# STM32W108 register map
File version: 1.0
Registers are 32-bit, read-write, reset 0x0 unless marked. A register's access mark holds for its fields unless they carry their own. Offsets are from the block's base; [hi:lo] are bit positions; {n}, {i} and the like mark numbered series.

## TIM2 — General purpose timer 2
Base 0x4000A804
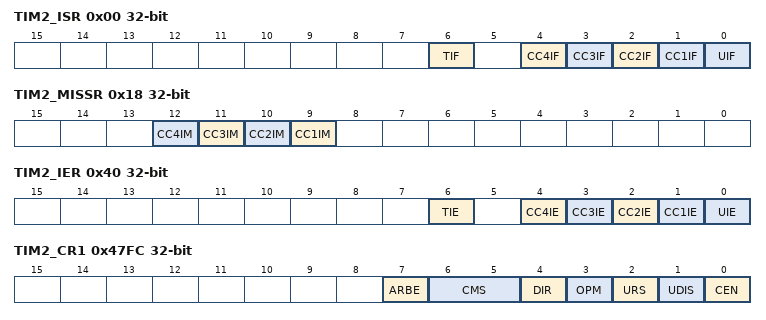
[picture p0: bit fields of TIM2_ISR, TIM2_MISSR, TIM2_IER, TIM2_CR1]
0x00 TIM2_ISR access per field — TIM Interrupt Status Register
  [6] TIF rw, [n] CC{n}IF rw (n=1..4), [0] UIF rw
0x18 TIM2_MISSR access per field — TIM interrupt missed register
  [n+8] CC{n}IM rw (n=1..4)
0x40 TIM2_IER — TIM Interrupt Enable Register
  [6] TIE, [n] CC{n}IE (n=1..4), [0] UIE
0x47FC TIM2_CR1 — control register 1
  [7] ARBE, [6:5] CMS, [4] DIR, [3] OPM, [2] URS, [1] UDIS, [0] CEN
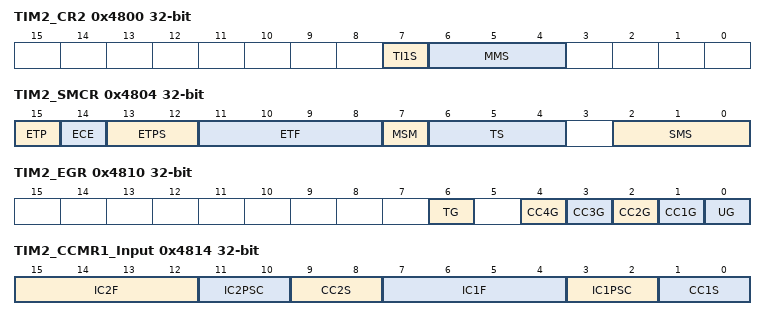
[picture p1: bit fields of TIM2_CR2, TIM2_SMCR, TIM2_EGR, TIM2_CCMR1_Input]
0x4800 TIM2_CR2 — control register 1
  [7] TI1S, [6:4] MMS
0x4804 TIM2_SMCR — TIM slave Mode Control register
  [15] ETP, [14] ECE, [13:12] ETPS, [11:8] ETF, [7] MSM, [6:4] TS, [2:0] SMS
0x4810 TIM2_EGR wo — TIM event generation register
  [6] TG, [n] CC{n}G (n=1..4), [0] UG
0x4814 TIM2_CCMR1_Input — capture/compare mode register 1 (Input mode)
  [15:12] IC2F, [11:10] IC2PSC, [9:8] CC2S, [7:4] IC1F, [3:2] IC1PSC, [1:0] CC1S
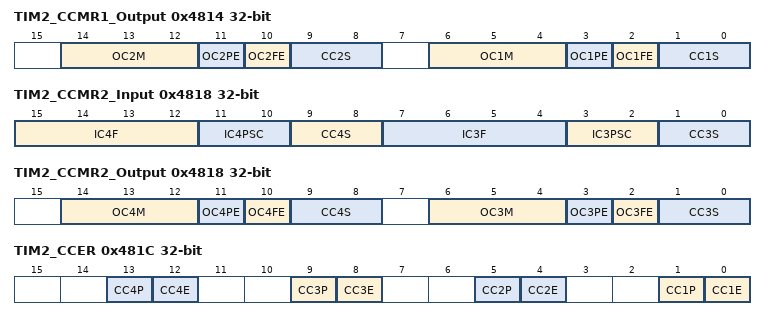
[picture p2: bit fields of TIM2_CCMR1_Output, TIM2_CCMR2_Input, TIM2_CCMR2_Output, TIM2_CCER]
0x4814 TIM2_CCMR1_Output (alternate view of TIM2_CCMR1_Input) — capture/compare mode register 1 (output mode)
  [14:12] OC2M, [11] OC2PE, [10] OC2FE, [9:8] CC2S, [6:4] OC1M, [3] OC1PE, [2] OC1FE, [1:0] CC1S
0x4818 TIM2_CCMR2_Input — capture/compare mode register 2 (input mode)
  [15:12] IC4F, [11:10] IC4PSC, [9:8] CC4S, [7:4] IC3F, [3:2] IC3PSC, [1:0] CC3S
0x4818 TIM2_CCMR2_Output (alternate view of TIM2_CCMR2_Input) — capture/compare mode register 2 (output mode)
  [14:12] OC4M, [11] OC4PE, [10] OC4FE, [9:8] CC4S, [6:4] OC3M, [3] OC3PE, [2] OC3FE, [1:0] CC3S
0x481C TIM2_CCER — TIM capture/compare enable register
  [4n-3] CC{n}P (n=1..4), [4n-4] CC{n}E (n=1..4)
0x4820 TIM2_CNT — TIM counter register
  [15:0] CNT
0x4824 TIM2_PSC — TIM prescaler register
  [15:0] PSC
0x4828 TIM2_ARR — TIM auto-reload register
  [15:0] ARR
{0x482C+4i} TIM2_CCR{i} (i=1..4) — TIM capture/compare register {i}
  [15:0] CCR
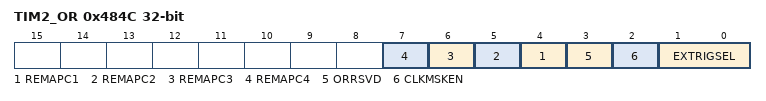
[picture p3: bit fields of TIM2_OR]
0x484C TIM2_OR — TIM option register
  [n+3] REMAPC{n} (n=1..4), [3] ORRSVD, [2] CLKMSKEN, [1:0] EXTRIGSEL

## SC1 — Serial controller 1
Base 0x4000A808
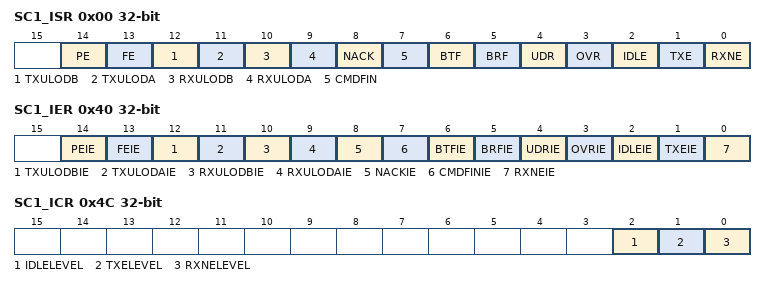
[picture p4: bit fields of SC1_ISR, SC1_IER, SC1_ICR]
0x00 SC1_ISR — Serial controller interrupt status register
  [14] PE, [13] FE, [12] TXULODB, [11] TXULODA, [10] RXULODB, [9] RXULODA, [8] NACK, [7] CMDFIN, [6] BTF, [5] BRF, [4] UDR, [3] OVR, [2] IDLE, [1] TXE, [0] RXNE
0x40 SC1_IER — Serial controller interrupt enable register
  [14] PEIE, [13] FEIE, [12] TXULODBIE, [11] TXULODAIE, [10] RXULODBIE, [9] RXULODAIE, [8] NACKIE, [7] CMDFINIE, [6] BTFIE, [5] BRFIE, [4] UDRIE, [3] OVRIE, [2] IDLEIE, [1] TXEIE, [0] RXNEIE
0x4C SC1_ICR — Serial controller interrupt control register
  [2] IDLELEVEL, [1] TXELEVEL, [0] RXNELEVEL
0x2034 SC1_DR — Serial control Data register
  [7:0] DR
0x204C SC1_CR — Serial controller control register
  [1:0] MODE
0x2058 SC1_CRR1 — Serial controller clock rate register
  [3:0] LIN
0x205C SC1_CRR2 — Serial controller clock rate register 2
  [3:0] EXP

## SC2 — Serial controller 2
Base 0x4000A80C
Registers as SC1 (with SC1 read as SC2), without SC1_DR, SC1_CR, SC1_CRR1, SC1_CRR2; these are added or differ:
0x1830 SC2_DR — Serial controller data register
  [7:0] DR
0x1848 SC2_CR — Serial controller control register
  [1:0] MODE
0x1854 SC2_CRR1 — Serial controller clock rate register 1
  [3:0] LIN
0x1858 SC2_CRR2 — Serial controller clock rate register 2
  [3:0] EXP

## ADC — Analog to Digital Converter
Base 0x4000A810
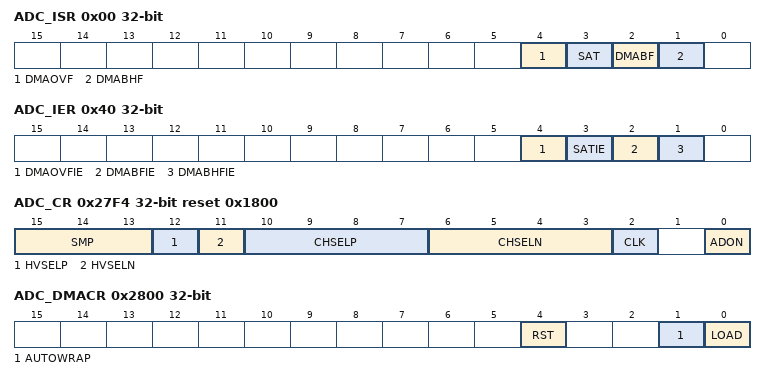
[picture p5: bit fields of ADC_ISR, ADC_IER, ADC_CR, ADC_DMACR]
0x00 ADC_ISR — ADC interrupt status register
  [4] DMAOVF, [3] SAT, [2] DMABF, [1] DMABHF
0x40 ADC_IER — ADC interrupt enable register
  [4] DMAOVFIE, [3] SATIE, [2] DMABFIE, [1] DMABHFIE
0x27F4 ADC_CR reset 0x1800 — ADC control register
  [15:13] SMP, [12] HVSELP, [11] HVSELN, [10:7] CHSELP, [6:3] CHSELN, [2] CLK, [0] ADON
0x27F8 ADC_OFFSETR — ADC offset register
  [15:0] OFFSET
0x27FC ADC_GAINR reset 0x8000 — ADC gain register
  [15:0] GAIN
0x2800 ADC_DMACR access per field — ADC DMA control register
  [4] RST wo — Write 1 to reset the ADC DMA
  [1] AUTOWRAP rw — Selects DMA mode
  [0] LOAD rw — Loads the DMA buffer
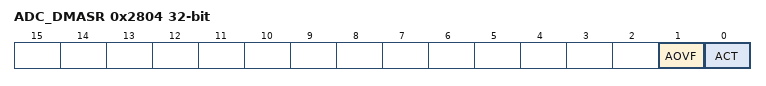
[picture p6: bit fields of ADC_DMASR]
0x2804 ADC_DMASR ro — ADC DMA status register
  [1] AOVF, [0] ACT
0x2808 ADC_DMAMSAR reset 0x20000000 — ADC DMA memory start address register
  [12:0] MSA
0x280C ADC_DMANDTR — ADC DMA number of data to transfer register
  [12:0] NDT
0x2810 ADC_DMAMNAR ro reset 0x20000000 — ADC DMA memory next address register
  [13:1] MNA
0x2814 ADC_DMACNDTR ro — ADC DMA count number of data transferred register
  [12:0] CNDT
